# CORE_CM register map
Vendor: Texas Instruments
Peripheral module from a debugger description file (folder omap36xx).
Registers are 32-bit, access per field, reset 0x0 unless marked. A register's access mark holds for its fields unless they carry their own. Offsets are as the file gives them; lines under a group give offsets from that group; [hi:lo] are bit positions; {n}, {i} and the like mark numbered series; 'fields as' and 'values as' point back to an identical list; <NAME> marks a mode.

## CORE_CM
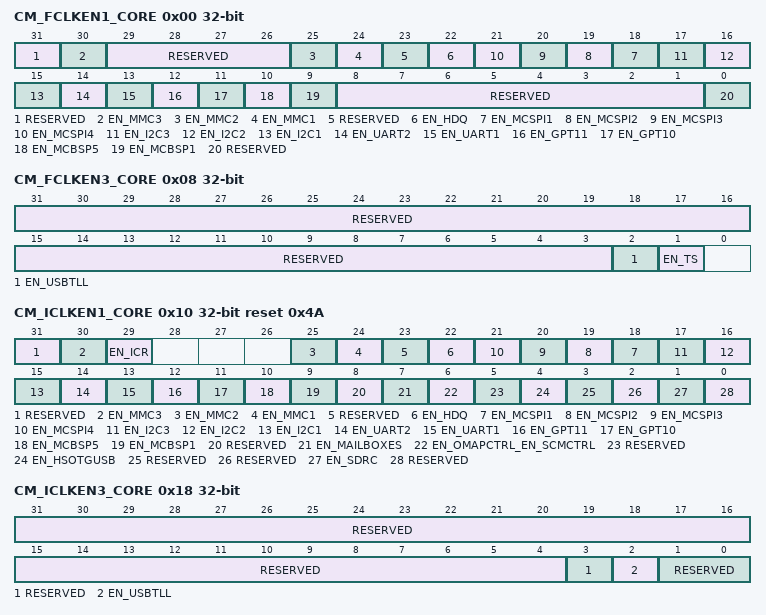
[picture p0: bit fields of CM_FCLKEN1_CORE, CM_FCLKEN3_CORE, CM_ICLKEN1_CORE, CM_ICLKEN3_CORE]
0x00 CM_FCLKEN1_CORE — Controls the module functional clock activity.
  [31] RESERVED rw — Write 0s for future compatibility. Read returns 0.
  [30] EN_MMC3 rw — MMC3 functional clock control.
    0=MMC3 functional clock is disabled; 1=MMC3 functional clock is enabled
  [29:26] RESERVED ro — Write 0s for future compatibility. Read returns 0.
  [25] EN_MMC2 rw — MMC2 functional clock control.
    0=MMC2 functional clock is disabled; 1=MMC2 functional clock is enabled
  [24] EN_MMC1 rw — MMC1 functional clock control.
    0=MMC 1 functional clock is disabled; 1=MMC 1 functional clock is enabled
  [23] RESERVED rw — Write 0s for future compatibility. Read returns 0.
  [22] EN_HDQ rw — HDQ-1 wire functional clock control.
    0=HDQ functional clock is disabled; 1=HDQ functional clock is enabled
  [n+17] EN_MCSPI{n} rw (n=1..4) — McSPI {n} functional clock control.
    0=McSPI {n} functional clock is disabled; 1=McSPI {n} functional clock is enabled
  [17] EN_I2C3 rw — I2C 3 functional clock control.
    0=I2C 3 functional clock is disabled; 1=I2C 3 functional clock is enabled
  [16] EN_I2C2 rw — I2C 2 functional clock control.
    0=I2C 2 functional clock is disabled; 1=I2C 2 functional clock is enabled
  [15] EN_I2C1 rw — I2C 1 functional clock control.
    0=I2C 1 functional clock is disabled; 1=I2C 1 functional clock is enabled
  [14] EN_UART2 rw — UART 2 functional clock control.
    0=UART 2 functional clock is disabled; 1=UART 2 functional clock is enabled
  [13] EN_UART1 rw — UART 1 functional clock control.
    0=UART 1 functional clock is disabled; 1=UART 1 functional clock is enabled
  [12] EN_GPT11 rw — GPTIMER 11 functional clock control.
    0=GPTIMER 11 functional clock is disabled; 1=GPTIMER 11 functional clock is enabled
  [11] EN_GPT10 rw — GPTIMER 10 functional clock control.
    0=GPTIMER 10 functional clock is disabled; 1=GPTIMER 10 functional clock is enabled
  [10] EN_MCBSP5 rw — McBSP 5 functional clock control.
    0=McBSP 5 functional clock is disabled; 1=McBSP 5 functional clock is enabled
  [9] EN_MCBSP1 rw — McBSP 1 functional clock control.
    0=McBSP 1 functional clock is disabled; 1=McBSP 1 functional clock is enabled
  [8:1] RESERVED ro — Write 0s for future compatibility. Read returns 0.
  [0] RESERVED rw — Write 0s for future compatibility. Read returns 0.
0x08 CM_FCLKEN3_CORE — Controls the module functional clock activity.
  [31:3] RESERVED ro — Write 0s for future compatibility. Read returns 0.
  [2] EN_USBTLL rw — USB TLL functional clock control.
    0=USB TLL functional clock is disabled; 1=USB TLL functional clock is enabled
  [1] EN_TS rw — Temperature Sensors functional clock control.
    0=Temperature Sensors functional clock is disabled (for both BandGap); 1=Temperature Sensors functional clock is enabled (for both BandGap)
0x10 CM_ICLKEN1_CORE reset 0x4A — Controls the modules interface clock activity.
  [31] RESERVED ro — Read returns 0.
  [30] EN_MMC3 rw — MMC SDIO 3 interface clock control.
    0=MMC 3 interface clock is disabled; 1=MMC 3 interface clock is enabled
  [29] EN_ICR rw — ICR interface clock control.
    0=ICR interface clock is disabled; 1=ICR interface clock is enabled
  [25] EN_MMC2 rw — MMC SDIO 2 interface clock control.
    0=MMC 2 interface clock is disabled; 1=MMC 2 interface clock is enabled
  [24] EN_MMC1 rw — MMC SDIO 1 interface clock control.
    0=MMC 1 interface clock is disabled; 1=MMC 1 interface clock is enabled
  [23] RESERVED rw — Write 0s for future compatibility. Read returns 0.
  [22] EN_HDQ rw — HDQ-wire interface clock control.
    0=HDQ interface clock is disabled; 1=HDQ interface clock is enabled
  [n+17] EN_MCSPI{n} rw (n=1..4) — McSPI {n} interface clock control.
    0=McSPI {n} interface clock is disabled; 1=McSPI {n} interface clock is enabled
  [17] EN_I2C3 rw — I2C 3 interface clock control.
    0=I2C 3 interface clock is disabled; 1=I2C 3 interface clock is enabled
  [16] EN_I2C2 rw — I2C 2 interface clock control.
    0=I2C 2 interface clock is disabled; 1=I2C 2 interface clock is enabled
  [15] EN_I2C1 rw — I2C 1 interface clock control.
    0=I2C 1 interface clock is disabled; 1=I2C 1 interface clock is enabled
  [14] EN_UART2 rw — UART 2 interface clock control.
    0=UART 2 interface clock is disabled; 1=UART 2 interface clock is enabled
  [13] EN_UART1 rw — UART 1 interface clock control.
    0=UART 1 interface clock is disabled; 1=UART 1 interface clock is enabled
  [12] EN_GPT11 rw — GPTIMER 11 interface clock control.
    0=GPTIMER 11 interface clock is disabled; 1=GPTIMER 11 interface clock is enabled
  [11] EN_GPT10 rw — GPTIMER 10 interface clock control.
    0=GPTIMER 10 interface clock is disabled; 1=GPTIMER 10 interface clock is enabled
  [10] EN_MCBSP5 rw — McBSP 5 interface clock control.
    0=McBSP 5 interface clock is disabled; 1=McBSP 5 interface clock is enabled
  [9] EN_MCBSP1 rw — McBSP 1 interface clock control.
    0=McBSP 1 interface clock is disabled; 1=McBSP 1 interface clock is enabled
  [8] RESERVED ro — Read returns 0.
  [7] EN_MAILBOXES rw — Mailboxes interface clock control
    0=Maiboxes interface clock is disabled; 1=Mailboxes interface clock is enabled
  [6] EN_OMAPCTRL_EN_SCMCTRL rw — System Control Module interface clock control
    0=EN_OMAPCTRL EN_SCMCTRL_0 (SCM interface clock is disabled); 1=EN_OMAPCTRL EN_SCMCTRL_1 (SCM interface clock is enabled)
  [5] RESERVED ro — Read returns 0.
  [4] EN_HSOTGUSB rw — HS OTG USB interface clock control.
    0=HS OTG USB interface clock is disabled; 1=HS OTG USB interface clock is enabled
  [3] RESERVED ro — Read returns 0.
  [2] RESERVED ro — Read returns 0.
  [1] EN_SDRC rw — SDRC interface clock control.
    0=SDRC interface clock is disabled; 1=SDRC interface clock is enabled
  [0] RESERVED rw — Read returns 0.
0x18 CM_ICLKEN3_CORE — Controls the module interface clock activity.
  [31:4] RESERVED ro — Write 0s for future compatibility. Read returns 0.
  [3] RESERVED rw — Write 0s for future compatibility. Read returns 0.
  [2] EN_USBTLL rw — USB TLL interface clock control.
    0=USB TLL interface clock is disabled; 1=USB TLL interface clock is enabled
  [1:0] RESERVED ro — Write 0s for future compatibility. Read returns 0.
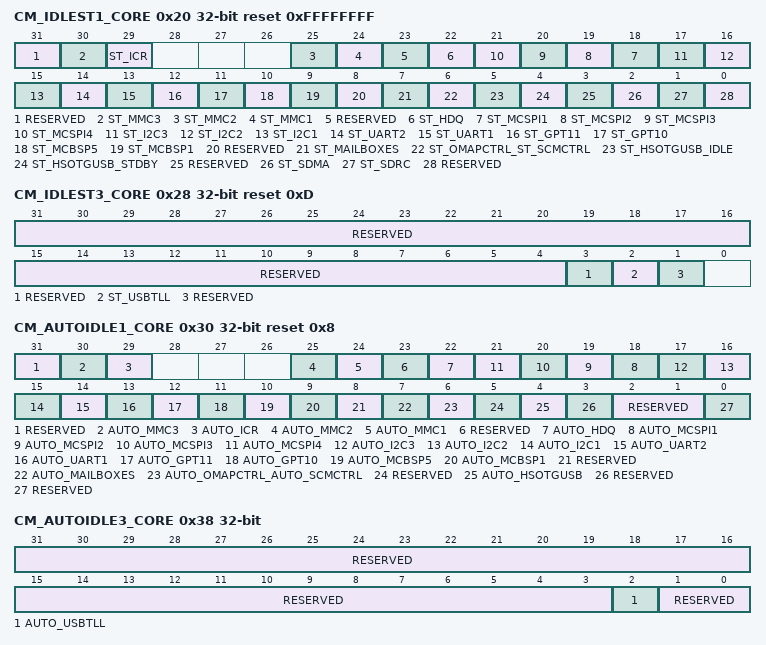
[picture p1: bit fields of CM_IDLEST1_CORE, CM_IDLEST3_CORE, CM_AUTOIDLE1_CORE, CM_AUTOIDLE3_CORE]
0x20 CM_IDLEST1_CORE ro reset 0xFFFFFFFF — CORE modules access availability monitoring. This register is read only and automatically updated.
  [31] RESERVED — Write 0s for future compatibility. Read returns 0.
  [30] ST_MMC3 — MMC 3 idle status.
    0=MMC 3 can be accessed; 1=MMC 3 cannot be accessed. Any access may return an error.
  [29] ST_ICR — ICR idle status.
    0=ICR can be accessed; 1=ICR cannot be accessed. Any access may return an error.
  [25] ST_MMC2 — MMC 2 idle status.
    0=MMC 2 can be accessed; 1=MMC 2 cannot be accessed. Any access may return an error.
  [24] ST_MMC1 — MMC SDIO 1 idle status.
    0=MMC 1 can be accessed; 1=MMC 1 cannot be accessed. Any access may return an error.
  [23] RESERVED — Read returns 1.
  [22] ST_HDQ — HDQ-1 wire idle status.
    0=HDQ can be accessed; 1=HDQ cannot be accessed. Any access may return an error.
  [n+17] ST_MCSPI{n} (n=1..4) — McSPI {n} idle status.
    0=McSPI {n} can be accessed; 1=McSPI {n} cannot be accessed. Any access may return an error.
  [17] ST_I2C3 — I2C 3 idle status.
    0=I2C 3 can be accessed; 1=I2C 3 cannot be accessed. Any access may return an error.
  [16] ST_I2C2 — I2C 2 idle status.
    0=I2C 2 can be accessed; 1=I2C 2 cannot be accessed. Any access may return an error.
  [15] ST_I2C1 — I2C 1 idle status.
    0=I2C 1 can be accessed; 1=I2C 1 cannot be accessed. Any access may return an error.
  [14] ST_UART2 — UART 2 idle status.
    0=UART 2 can be accessed; 1=UART 2 cannot be accessed. Any access may return an error.
  [13] ST_UART1 — UART 1 idle status.
    0=UART 1 can be accessed; 1=UART 1 cannot be accessed. Any access may return an error.
  [12] ST_GPT11 — GPTIMER 11 idle status.
    0=GPTIMER 11 can be accessed; 1=GPTIMER 11 cannot be accessed. Any access may return an error.
  [11] ST_GPT10 — GPTIMER 10 idle status.
    0=GPTIMER 10 can be accessed; 1=GPTIMER 10 cannot be accessed. Any access may return an error.
  [10] ST_MCBSP5 — McBSP 5 idle status.
    0=McBSP 5 can be accessed; 1=McBSP 5 cannot be accessed. Any access may return an error.
  [9] ST_MCBSP1 — McBSP 1 idle status.
    0=McBSP 1 can be accessed; 1=McBSP 1 cannot be accessed. Any access may return an error.
  [8] RESERVED — Read undefined.
  [7] ST_MAILBOXES — Mailboxes idle status
    0=Mailboxes can be accessed; 1=Mailboxes cannot be accessed. Any access may return an error.
  [6] ST_OMAPCTRL_ST_SCMCTRL — System Control Module idle status
    0=SCM can be accessed; 1=SCM cannot be accessed. Any access may return an error.
  [5] ST_HSOTGUSB_IDLE — HS OTG USB idle status.
    0=HS OTG USB can be accessed; 1=HS OTG USB cannot be accessed. Any access may return an error.
  [4] ST_HSOTGUSB_STDBY — HS OTG USB standby status.
    0=HS OTG USB is active; 1=HS OTG USB is in standby mode
  [3] RESERVED — Read returns 1.
  [2] ST_SDMA — System DMA standby status.
    0=System DMA is active; 1=System DMA is in standby mode
  [1] ST_SDRC — SDRC idle status.
    0=SDRC can be accessed; 1=SDRC cannot be accessed. Any access may return an error.
  [0] RESERVED — Read returns 1.
0x28 CM_IDLEST3_CORE ro reset 0xD — CORE modules access availability monitoring. This register is read only and automatically updated.
  [31:4] RESERVED — Write 0s for future compatibility. Read returns 0.
  [3] RESERVED — Read returns 1.
  [2] ST_USBTLL — USB TLL idle status.
    0=USB TLL can be accessed; 1=USB TLL cannot be accessed. Any access may return an error.
  [1] RESERVED — Write 0s for future compatibility. Read returns 0.
0x30 CM_AUTOIDLE1_CORE reset 0x8 — This register controls the automatic control of the CORE modules interface clock activity.
  [31] RESERVED rw — Write 0s for future compatibility. Read returns 0.
  [30] AUTO_MMC3 rw — MMC SDIO 3 auto clock control.
    0=MMC 3 interface clock is unrelated to the domain state transition; 1=MMC 3 interface clock is automatically enabled or disabled along with the domain state transition
  [29] AUTO_ICR rw — ICR auto clock control.
    0=ICR interface clock is unrelated to the domain state transition; 1=ICR interface clock is automatically enabled or disabled along with the domain state transition
  [25] AUTO_MMC2 rw — MMC SDIO 2 auto clock control.
    0=MMC 2 interface clock is unrelated to the domain state transition; 1=MMC 2 interface clock is automatically enabled or disabled along with the domain state transition
  [24] AUTO_MMC1 rw — MMC SDIO 1 auto clock control.
    0=MMC 1 interface clock is unrelated to the domain state transition; 1=MMC 1 interface clock is automatically enabled or disabled along with the domain state transition
  [23] RESERVED rw — Read returns 0.
  [22] AUTO_HDQ rw — HDQ-1 wire auto clock control.
    0=HDQ interface clock is unrelated to the domain state transition; 1=HDQ interface clock is automatically enabled or disabled along with the domain state transition
  [n+17] AUTO_MCSPI{n} rw (n=1..4) — McSPI {n} auto clock control.
    0=McSPI {n} interface clock is unrelated to the domain state transition; 1=McSPI {n} interface clock is automatically enabled or disabled along with the domain state transition
  [17] AUTO_I2C3 rw — I2C 3 auto clock control.
    0=I2C 3 interface clock is unrelated to the domain state transition; 1=I2C 3 interface clock is automatically enabled or disabled along with the domain state transition
  [16] AUTO_I2C2 rw — I2C 2 auto clock control.
    0=I2C 2 interface clock is unrelated to the domain state transition; 1=I2C 2 interface clock is automatically enabled or disabled along with the domain state transition
  [15] AUTO_I2C1 rw — I2C 1 auto clock control.
    0=I2C 1 interface clock is unrelated to the domain state transition; 1=I2C 1 interface clock is automatically enabled or disabled along with the domain state transition
  [14] AUTO_UART2 rw — UART 2 auto clock control.
    0=UART 2 interface clock is unrelated to the domain state transition; 1=UART 2 interface clock is automatically enabled or disabled along with the domain state transition
  [13] AUTO_UART1 rw — UART 1 auto clock control.
    0=UART 1 interface clock is unrelated to the domain state transition; 1=UART 1 interface clock is automatically enabled or disabled along with the domain state transition
  [12] AUTO_GPT11 rw — GPTIMER 11 auto clock control.
    0=GPTIMER 11 interface clock is unrelated to the domain state transition; 1=GPTIMER 11 interface clock is automatically enabled or disabled along with the domain state transition
  [11] AUTO_GPT10 rw — GPTIMER 10 auto clock control.
    0=GPTIMER 10 interface clock is unrelated to the domain state transition; 1=GPTIMER 10 interface clock is automatically enabled or disabled along with the domain state transition
  [10] AUTO_MCBSP5 rw — McBSP 5 auto clock control.
    0=McBSP 5 interface clock is unrelated to the domain state transition; 1=McBSP 5 interface clock is automatically enabled or disabled along with the domain state transition
  [9] AUTO_MCBSP1 rw — McBSP 1 auto clock control.
    0=McBSP 1 interface clock is unrelated to the domain state transition; 1=McBSP 1 interface clock is automatically enabled or disabled along with the domain state transition
  [8] RESERVED ro — Read returns 0.
  [7] AUTO_MAILBOXES rw — Mailboxes auto clock control
    0=Mailboxes interface clock is unrelated to the domain state transition; 1=Mailboxes interface clock is automatically enabled or disabled along with the domain state transition
  [6] AUTO_OMAPCTRL_AUTO_SCMCTRL rw — System Control Module auto clock control
    0=AUTO_OMAPCTRL AUTO_SCMCTRL_0 (SCM interface clock is unrelated to the domain state transition.); 1=AUTO_OMAPCTRL AUTO_SCMCTRL_1 (SCM interface clock is automatically enabled or disabled along with the domain state transition.)
  [5] RESERVED ro — Read returns 0.
  [4] AUTO_HSOTGUSB rw — HS OTG USB auto clock control.
    0=HS OTG USB interface clock is unrelated to the domain state transition; 1=HS OTG USB interface clock is automatically enabled or disabled along with the domain state transition
  [3] RESERVED rw — Write 1s for future compatibility. Read returns 1.
  [2:1] RESERVED ro — Read returns 0.
  [0] RESERVED rw — Write 0s for future compatibility. Read returns 0.
0x38 CM_AUTOIDLE3_CORE — This register controls the automatic control of the CORE modules interface clock activity.
  [31:3] RESERVED ro — Write 0s for future compatibility. Read returns 0.
  [2] AUTO_USBTLL rw — USB TLL auto clock control.
    0=USB TLL interface clock is unrelated to the domain state transition; 1=USB TLL interface clock is automatically enabled or disabled along with the domain state transition
  [1:0] RESERVED ro — Write 0s for future compatibility. Read returns 0.
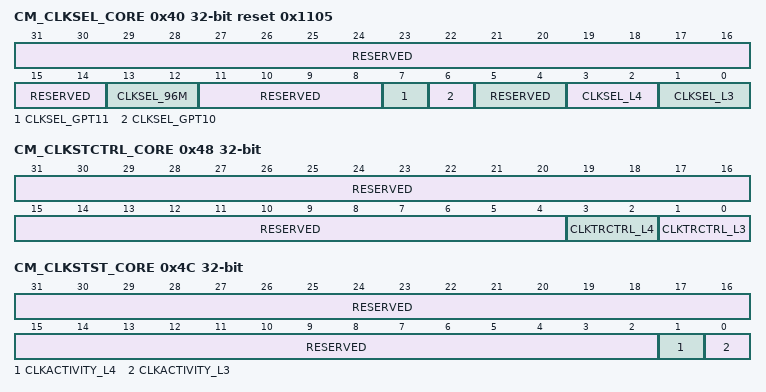
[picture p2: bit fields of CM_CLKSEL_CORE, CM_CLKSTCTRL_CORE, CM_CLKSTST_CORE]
0x40 CM_CLKSEL_CORE reset 0x1105 — CORE modules clock selection.
  [31:14] RESERVED ro — Write 0s for future compatibility. Read returns 0.
  [13:12] CLKSEL_96M rw — Selects the 96 MHz clock; Other enums: Reserved.
    1=The clock 96 MHz is the DPLL4_M2_CLK divided by 1; 2=The clock 96 MHz is the DPLL4_M2_CLK divided by 2
  [11:8] RESERVED rw — Write the reset value, read returns reset value.
  [7] CLKSEL_GPT11 rw — Selects GPTIMER 11 source clock
    0=source is CM_32K_CLK; 1=source is CM_SYS_CLK
  [6] CLKSEL_GPT10 rw — Selects GPTIMER 10 source clock
    0=source is CM_32K_CLK; 1=source is CM_SYS_CLK
  [5:4] RESERVED ro — Write 0s for future compatibility. Read returns 0.
  [3:2] CLKSEL_L4 rw — Selects Peripherals interconnect clock (L4_CLK); Other enums: Reserved
    1=L4_CLK is L3_CLK divided by 1 (boot mode only); 2=L4_CLK is L3_CLK divided by 2
  [1:0] CLKSEL_L3 rw — Selects L3 interconnect clock (L3_CLK); Other enums: Reserved
    1=L3_CLK is CORE_CLK divided by 1; 2=L3_CLK is CORE_CLK divided by 2
0x48 CM_CLKSTCTRL_CORE — This register enables the domain power state transition. It controls the HW supervised domain power state transition between ACTIVE and INACTIVE states.
  [31:4] RESERVED ro — Write 0s for future compatibility. Read returns 0.
  [3:2] CLKTRCTRL_L4 rw — Controls the clock state transition of the L4 clock domain.
    0=Automatic transition is disabled; 3=Automatic transition is enabled. Transition is supervised by the HardWare.
  [1:0] CLKTRCTRL_L3 rw — Controls the clock state transition of the L3 clock domain.
    values as CLKTRCTRL_L4
0x4C CM_CLKSTST_CORE ro — This register provides a status on the interface clock activity in the domain.
  [31:2] RESERVED — Write 0s for future compatibility. Read returns 0.
  [1] CLKACTIVITY_L4 — L4_ICLK interface clock activity status
    0=No domain interface clock activity; 1=Domain interface clock is active
  [0] CLKACTIVITY_L3 — L3_ICLK interface clock activity status
    values as CLKACTIVITY_L4
